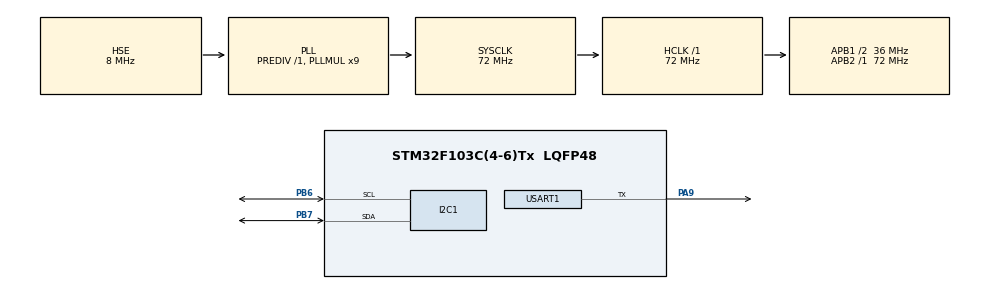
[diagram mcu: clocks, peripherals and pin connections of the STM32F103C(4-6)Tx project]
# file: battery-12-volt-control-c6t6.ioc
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Mcu.Family=STM32F1
Mcu.Name=STM32F103C(4-6)Tx
Mcu.Package=LQFP48
NVIC.PriorityGroup=NVIC_PRIORITYGROUP_4
NVIC.RTC_Alarm_IRQn=true\:0\:0\:false\:false\:true\:true\:true\:true
PA13.Mode=Serial_Wire
PA13.Signal=SYS_JTMS-SWDIO
PA14.Mode=Serial_Wire
PA14.Signal=SYS_JTCK-SWCLK
PA9.Mode=Half_duplex(single_wire_mode)
PA9.Signal=USART1_TX
PB6.Mode=I2C
PB6.Signal=I2C1_SCL
PB7.Mode=I2C
PB7.Signal=I2C1_SDA
PC14-OSC32_IN.Mode=LSE-External-Oscillator
PC14-OSC32_IN.Signal=RCC_OSC32_IN
PC15-OSC32_OUT.Mode=LSE-External-Oscillator
PC15-OSC32_OUT.Signal=RCC_OSC32_OUT
PD0-OSC_IN.Mode=HSE-External-Oscillator
PD0-OSC_IN.Signal=RCC_OSC_IN
PD1-OSC_OUT.Mode=HSE-External-Oscillator
PD1-OSC_OUT.Signal=RCC_OSC_OUT
ProjectManager.HeapSize=0x200
ProjectManager.StackSize=0x400
ProjectManager.TargetToolchain=STM32CubeIDE
RCC.AHBFreq_Value=72000000
RCC.APB1CLKDivider=RCC_HCLK_DIV2
RCC.APB1Freq_Value=36000000
RCC.APB1TimFreq_Value=72000000
RCC.APB2Freq_Value=72000000
RCC.APB2TimFreq_Value=72000000
RCC.HCLKFreq_Value=72000000
RCC.PLLMUL=RCC_PLL_MUL9
RCC.PLLSourceVirtual=RCC_PLLSOURCE_HSE
RCC.RTCClockSelection=RCC_RTCCLKSOURCE_LSE
RCC.SYSCLKFreq_VALUE=72000000
RCC.SYSCLKSource=RCC_SYSCLKSOURCE_PLLCLK
RCC.USBFreq_Value=72000000
RTC.Format=RTC_FORMAT_BIN
USART1.Mode=MODE_TX
USART1.VirtualMode=VM_ASYNC
VP_RTC_VS_RTC_Activate.Mode=RTC_Enabled
board=custom

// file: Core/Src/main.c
/* USER CODE BEGIN Header */
/**
  ******************************************************************************
  * @file           : main.c
  * @brief          : Main program body
  ******************************************************************************
  * @attention
  *
  * Copyright (c) 2022 STMicroelectronics.
  * All rights reserved.
  *
  * This software is licensed under terms that can be found in the LICENSE file
  * in the root directory of this software component.
  * If no LICENSE file comes with this software, it is provided AS-IS.
  *
  ******************************************************************************
  */
/* USER CODE END Header */
#include "main.h"
#include "i2c.h"
#include "rtc.h"
#include "usart.h"
#include "gpio.h"

/* USER CODE BEGIN Includes */

	#include "stdio.h"
	#include <string.h>
	#include "lcd1602_fc113_sm.h"

/* USER CODE END Includes */

/* USER CODE BEGIN PTD */

	#define 	MY_DEBUG
	#define 	UART_DEBUG		&huart1
	#define 	SOFT_VERSION	1101
	//#define		LCD1602

/* USER CODE END PTD */

/* USER CODE BEGIN PV */
	uint8_t alarma = 0;
/* USER CODE END PV */

void SystemClock_Config(void);
/* USER CODE BEGIN PFP */

	void UartDebug(char* _text) ;
	void StmSleep(void) 		;
	void StmStop(void) 			;

/* USER CODE END PFP */

int main(void)
{

  /* MCU Configuration--------------------------------------------------------*/

  /* Reset of all peripherals, Initializes the Flash interface and the Systick. */
  HAL_Init();

  /* Configure the system clock */
  SystemClock_Config();

  /* Initialize all configured peripherals */
  MX_GPIO_Init();
  MX_RTC_Init();
  MX_USART1_UART_Init();
  MX_I2C1_Init();
  /* USER CODE BEGIN 2 */

	char DataChar[100];
	int soft_version_arr_int[3];
	soft_version_arr_int[0] = ((SOFT_VERSION) / 1000) %10 ;
	soft_version_arr_int[1] = ((SOFT_VERSION) /   10) %100 ;
	soft_version_arr_int[2] = ((SOFT_VERSION)       ) %10 ;

	sprintf(DataChar,"\r\n\r\n\tBattery 12 Volt control v%d.%02d.%d " ,
	soft_version_arr_int[0] , soft_version_arr_int[1] , soft_version_arr_int[2] );
	UartDebug(DataChar) ;

	#define DATE_as_int_str 	(__DATE__)
	#define TIME_as_int_str 	(__TIME__)
	sprintf(DataChar,"\r\n\tBuild: %s. Time: %s." , DATE_as_int_str , TIME_as_int_str ) ;
	UartDebug(DataChar) ;

	sprintf(DataChar,"\r\n\tFor debug: UART1-115200/8-N-1\r\n" );
	UartDebug(DataChar) ;
	int counter = 0;
	//		ADC1_Init(&hadc1, ADC_CHANNEL) ;
	//		uint32_t adc1_init_value;
	//		sprintf(DataChar,"ADC for blink: "); UartDebug(DataChar) ;
	//		adc1_init_value = ADC1_GetValue( &hadc1, ADC_CHANNEL ) ;
	//		adc1_init_value = (1000 * adc1_init_value) / ADC_COEFFICIENT;
	//		sprintf(DataChar, "%lu.%02luV, ", adc1_init_value/100, adc1_init_value%100 ); UartDebug(DataChar) ;
	//		sprintf(DataChar,"\r\n"); UartDebug(DataChar) ;

	RTC_TimeTypeDef TimeSt = { 0 } ;
	HAL_RTC_GetTime(&hrtc, &TimeSt, RTC_FORMAT_BIN);
	sprintf(DataChar,"RTC Time: %02d:%02d:%02d \r\n",TimeSt.Hours, TimeSt.Minutes, TimeSt.Seconds );
	UartDebug(DataChar);
	alarma = 1 ;

//		#define ADR_I2C_FC113 0x27

		lcd1602_fc113_struct h1_lcd1602_fc113 =
		{
			.i2c = &hi2c1,
			.device_i2c_address = ADR_I2C_FC113
		};

		//LCD1602_Scan_I2C_bus(&h1_lcd1602_fc113);

		LCD1602_Scan_I2C_to_UART(&hi2c1, &huart1);

		LCD1602_Init(&h1_lcd1602_fc113);

		LCD1602_Clear(&h1_lcd1602_fc113);
		sprintf(DataChar,"Steps Counter\r\n");
		LCD1602_Print_Line(&h1_lcd1602_fc113, DataChar, strlen(DataChar));
		UartDebug(DataChar);
		sprintf(DataChar," STP100M\r\n");
		LCD1602_Print_Line(&h1_lcd1602_fc113, DataChar, strlen(DataChar));
		UartDebug(DataChar);
		HAL_Delay(1000);
		LCD1602_Clear(&h1_lcd1602_fc113);

  /* USER CODE END 2 */

  /* Infinite loop */
  /* USER CODE BEGIN WHILE */
  while (1)
  {
	sprintf(DataChar,"%d ", counter++ ); UartDebug(DataChar);
	//HAL_GPIO_TogglePin(LED_GPIO_Port,LED_Pin);
	HAL_Delay(1000);
	//HAL_IWDG_Refresh(&hiwdg);

	if (alarma == 1) {
		//HAL_IWDG_Refresh(&hiwdg);
		RTC_TimeTypeDef TimeSt = { 0 } ;
		HAL_RTC_GetTime(&hrtc, &TimeSt, RTC_FORMAT_BIN);
		//sprintf(DataChar,"RTC  time: %02d:%02d:%02d\r\n",TimeSt.Hours, TimeSt.Minutes, TimeSt.Seconds ); UartDebug(DataChar) ;
		RTC_AlarmTypeDef AlarmSt = {0};
		AlarmSt.Alarm = 0;
		AlarmSt.AlarmTime.Hours   = TimeSt.Hours 		;
		AlarmSt.AlarmTime.Minutes = TimeSt.Minutes + 0	;
		AlarmSt.AlarmTime.Seconds = TimeSt.Seconds + 5	;
		sprintf(DataChar,"set alarm: %02d:%02d:%02d ",AlarmSt.AlarmTime.Hours, AlarmSt.AlarmTime.Minutes, AlarmSt.AlarmTime.Seconds ); UartDebug(DataChar) ;
		HAL_StatusTypeDef alarm_status= HAL_RTC_SetAlarm_IT(&hrtc, &AlarmSt, RTC_FORMAT_BIN);
		sprintf(DataChar," (status: %d) \r\n", alarm_status); UartDebug(DataChar);
		alarma = 0;
	}

    /* USER CODE END WHILE */

  }
}

void SystemClock_Config(void)
{
  RCC_OscInitTypeDef RCC_OscInitStruct = {0};
  RCC_ClkInitTypeDef RCC_ClkInitStruct = {0};
  RCC_PeriphCLKInitTypeDef PeriphClkInit = {0};

  /** Initializes the RCC Oscillators according to the specified parameters
  * in the RCC_OscInitTypeDef structure.
  */
  RCC_OscInitStruct.OscillatorType = RCC_OSCILLATORTYPE_HSE|RCC_OSCILLATORTYPE_LSE;
  RCC_OscInitStruct.HSEState = RCC_HSE_ON;
  RCC_OscInitStruct.HSEPredivValue = RCC_HSE_PREDIV_DIV1;
  RCC_OscInitStruct.LSEState = RCC_LSE_ON;
  RCC_OscInitStruct.HSIState = RCC_HSI_ON;
  RCC_OscInitStruct.PLL.PLLState = RCC_PLL_ON;
  RCC_OscInitStruct.PLL.PLLSource = RCC_PLLSOURCE_HSE;
  RCC_OscInitStruct.PLL.PLLMUL = RCC_PLL_MUL9;
  if (HAL_RCC_OscConfig(&RCC_OscInitStruct) != HAL_OK)
  {
    Error_Handler();
  }

  /** Initializes the CPU, AHB and APB buses clocks
  */
  RCC_ClkInitStruct.ClockType = RCC_CLOCKTYPE_HCLK|RCC_CLOCKTYPE_SYSCLK
                              |RCC_CLOCKTYPE_PCLK1|RCC_CLOCKTYPE_PCLK2;
  RCC_ClkInitStruct.SYSCLKSource = RCC_SYSCLKSOURCE_PLLCLK;
  RCC_ClkInitStruct.AHBCLKDivider = RCC_SYSCLK_DIV1;
  RCC_ClkInitStruct.APB1CLKDivider = RCC_HCLK_DIV2;
  RCC_ClkInitStruct.APB2CLKDivider = RCC_HCLK_DIV1;

  if (HAL_RCC_ClockConfig(&RCC_ClkInitStruct, FLASH_LATENCY_2) != HAL_OK)
  {
    Error_Handler();
  }
  PeriphClkInit.PeriphClockSelection = RCC_PERIPHCLK_RTC;
  PeriphClkInit.RTCClockSelection = RCC_RTCCLKSOURCE_LSE;
  if (HAL_RCCEx_PeriphCLKConfig(&PeriphClkInit) != HAL_OK)
  {
    Error_Handler();
  }
}

/* USER CODE BEGIN 4 */

void UartDebug(char* _text) {
#ifdef MY_DEBUG
	HAL_UART_Transmit(UART_DEBUG, (uint8_t*)_text, strlen(_text), 100);
#endif
} //**************************************************************************

void StmSleep(void) {
#ifdef STOP_PRINT
	sprintf(DataChar, "sleep.. "); UartDebug(DataChar) ;
#endif
	#ifdef MASTER
		HAL_IWDG_Refresh(&hiwdg);
	#endif
    HAL_SuspendTick();
	HAL_PWR_EnterSLEEPMode(	PWR_MAINREGULATOR_ON, PWR_SLEEPENTRY_WFI );	//	Sec in Sec
	// -> Sleep MODE <- //
	SystemClock_Config();
	HAL_ResumeTick();
#ifdef STOP_PRINT
	sprintf(DataChar, "^ "); UartDebug(DataChar) ;
#endif
} //**************************************************************************

void StmStop(void) {
#ifdef STOP_PRINT
	sprintf(DataChar, "Stop mode...\r\n\r\n"); UartDebug(DataChar) ;
#endif
#ifdef MASTER
	HAL_IWDG_Refresh(&hiwdg);
#endif
    HAL_SuspendTick();
	HAL_PWR_EnterSTOPMode(	PWR_LOWPOWERREGULATOR_ON,	PWR_STOPENTRY_WFI  );
	// -> STOP MODE <- //
    SystemClock_Config();
	HAL_ResumeTick();
#ifdef STOP_PRINT
	sprintf(DataChar, "WakeUp.\r\n"); UartDebug(DataChar) ;
#endif
} //**************************************************************************

void HAL_RTC_AlarmAEventCallback(RTC_HandleTypeDef *hrtc) {
	char		_text[40]	= { 0 } ;
	sprintf(_text," AlarmA: ") ;
	HAL_UART_Transmit(&huart1, (uint8_t*)_text, strlen(_text), 100);

	RTC_TimeTypeDef TimeSt = { 0 } ;
	HAL_RTC_GetTime(hrtc, &TimeSt, RTC_FORMAT_BIN);

	sprintf(_text,"%02d:%02d:%02d\r\n",TimeSt.Hours, TimeSt.Minutes, TimeSt.Seconds );
	UartDebug(_text);
	alarma = 1;
} //**************************************************************************

/* USER CODE END 4 */

void Error_Handler(void)
{
  __disable_irq();
  while (1)
  {
  }
}
